# STM32L4x6 register map
File version: 1.5
CPU: CM4 r1p0, little endian, no MPU, FPU, 3 interrupt priority bits
Registers are 32-bit, read-write, reset 0x0 unless marked. A register's access mark holds for its fields unless they carry their own. Offsets are from the block's base; [hi:lo] are bit positions; {n}, {i} and the like mark numbered series; 'fields as' and 'values as' point back to an identical list.

## OTG_FS_HOST — USB on the go full speed
Base 0x50000400
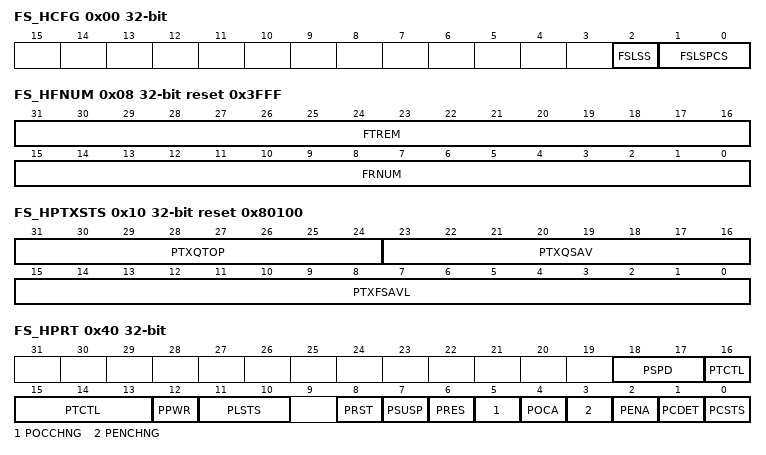
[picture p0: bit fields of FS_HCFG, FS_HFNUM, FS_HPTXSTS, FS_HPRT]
0x00 FS_HCFG access per field — OTG_FS host configuration register (OTG_FS_HCFG)
  [2] FSLSS ro — FS- and LS-only support
  [1:0] FSLSPCS rw — FS/LS PHY clock select
0x04 HFIR reset 0xEA60 — OTG_FS Host frame interval register
  [15:0] FRIVL — Frame interval
0x08 FS_HFNUM ro reset 0x3FFF — OTG_FS host frame number/frame time remaining register (OTG_FS_HFNUM)
  [31:16] FTREM — Frame time remaining
  [15:0] FRNUM — Frame number
0x10 FS_HPTXSTS access per field reset 0x80100 — OTG_FS_Host periodic transmit FIFO/queue status register (OTG_FS_HPTXSTS)
  [31:24] PTXQTOP ro — Top of the periodic transmit request queue
  [23:16] PTXQSAV ro — Periodic transmit request queue space available
  [15:0] PTXFSAVL rw — Periodic transmit data FIFO space available
0x14 HAINT ro — OTG_FS Host all channels interrupt register
  [15:0] HAINT — Channel interrupts
0x18 HAINTMSK — OTG_FS host all channels interrupt mask register
  [15:0] HAINTM — Channel interrupt mask
0x40 FS_HPRT access per field — OTG_FS host port control and status register (OTG_FS_HPRT)
  [18:17] PSPD ro — Port speed
  [16:13] PTCTL rw — Port test control
  [12] PPWR rw — Port power
  [11:10] PLSTS ro — Port line status
  [8] PRST rw — Port reset
  [7] PSUSP rw — Port suspend
  [6] PRES rw — Port resume
  [5] POCCHNG rw — Port overcurrent change
  [4] POCA ro — Port overcurrent active
  [3] PENCHNG rw — Port enable/disable change
  [2] PENA rw — Port enable
  [1] PCDET rw — Port connect detected
  [0] PCSTS ro — Port connect status
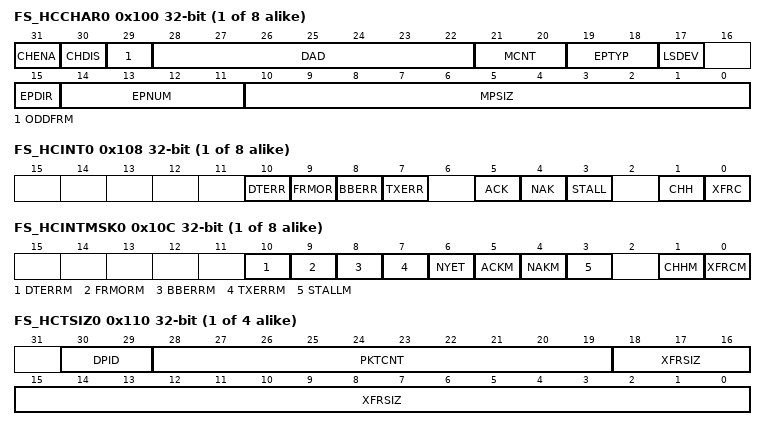
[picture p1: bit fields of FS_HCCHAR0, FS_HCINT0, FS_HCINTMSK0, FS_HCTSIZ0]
{0x100+0x20*i} FS_HCCHAR{i} (i=0..7) — OTG_FS host channel-{i} characteristics register (OTG_FS_HCCHAR{i})
  [31] CHENA — Channel enable
  [30] CHDIS — Channel disable
  [29] ODDFRM — Odd frame
  [28:22] DAD — Device address
  [21:20] MCNT — Multicount
  [19:18] EPTYP — Endpoint type
  [17] LSDEV — Low-speed device
  [15] EPDIR — Endpoint direction
  [14:11] EPNUM — Endpoint number
  [10:0] MPSIZ — Maximum packet size
{0x108+0x20*i} FS_HCINT{i} (i=0..7) — OTG_FS host channel-{i} interrupt register (OTG_FS_HCINT{i})
  [10] DTERR — Data toggle error
  [9] FRMOR — Frame overrun
  [8] BBERR — Babble error
  [7] TXERR — Transaction error
  [5] ACK — ACK response received/transmitted interrupt
  [4] NAK — NAK response received interrupt
  [3] STALL — STALL response received interrupt
  [1] CHH — Channel halted
  [0] XFRC — Transfer completed
{0x10C+0x20*i} FS_HCINTMSK{i} (i=0..7) — OTG_FS host channel-{i} mask register (OTG_FS_HCINTMSK{i})
  [10] DTERRM — Data toggle error mask
  [9] FRMORM — Frame overrun mask
  [8] BBERRM — Babble error mask
  [7] TXERRM — Transaction error mask
  [6] NYET — response received interrupt mask
  [5] ACKM — ACK response received/transmitted interrupt mask
  [4] NAKM — NAK response received interrupt mask
  [3] STALLM — STALL response received interrupt mask
  [1] CHHM — Channel halted mask
  [0] XFRCM — Transfer completed mask
{0x110+0x20*i} FS_HCTSIZ{i} (i=0..3) — OTG_FS host channel-{i} transfer size register
  [30:29] DPID — Data PID
  [28:19] PKTCNT — Packet count
  [18:0] XFRSIZ — Transfer size
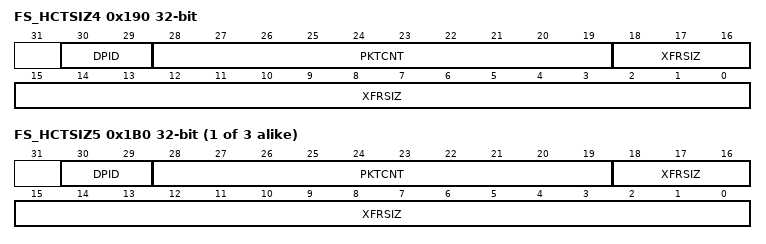
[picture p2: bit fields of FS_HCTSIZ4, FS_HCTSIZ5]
0x190 FS_HCTSIZ4 — OTG_FS host channel-x transfer size register
  fields as FS_HCTSIZ0
{0x110+0x20*i} FS_HCTSIZ{i} (i=5..7) — OTG_FS host channel-{i} transfer size register
  fields as FS_HCTSIZ0

## OTG_FS_PWRCLK — USB on the go full speed
Base 0x50000E00
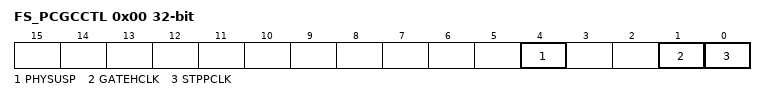
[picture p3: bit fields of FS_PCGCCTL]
0x00 FS_PCGCCTL — OTG_FS power and clock gating control register (OTG_FS_PCGCCTL)
  [4] PHYSUSP — PHY Suspended
  [1] GATEHCLK
  [0] STPPCLK — Stop PHY clock

## SWPMI1 — Single Wire Protocol Master Interface
Base 0x40008800
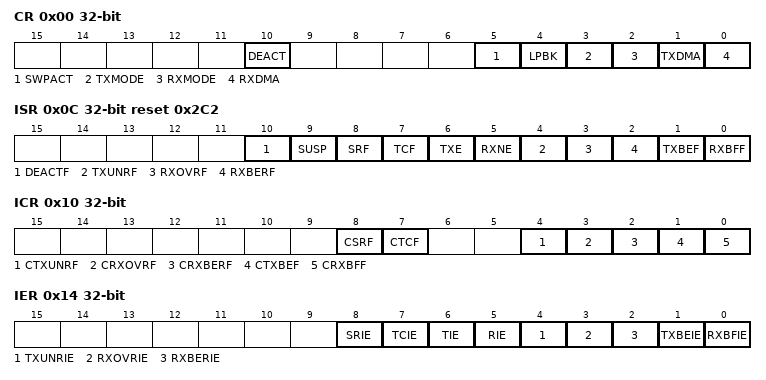
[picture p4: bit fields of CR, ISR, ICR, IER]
0x00 CR — SWPMI Configuration/Control register
  [10] DEACT — Single wire protocol master interface deactivate
  [5] SWPACT — Single wire protocol master interface activate
  [4] LPBK — Loopback mode enable
  [3] TXMODE — Transmission buffering mode
  [2] RXMODE — Reception buffering mode
  [1] TXDMA — Transmission DMA enable
  [0] RXDMA — Reception DMA enable
0x04 BRR reset 0x1 — SWPMI Bitrate register
  [5:0] BR — Bitrate prescaler
0x0C ISR ro reset 0x2C2 — SWPMI Interrupt and Status register
  [10] DEACTF — DEACTIVATED flag
  [9] SUSP — SUSPEND flag
  [8] SRF — Slave resume flag
  [7] TCF — Transfer complete flag
  [6] TXE — Transmit data register empty
  [5] RXNE — Receive data register not empty
  [4] TXUNRF — Transmit underrun error flag
  [3] RXOVRF — Receive overrun error flag
  [2] RXBERF — Receive CRC error flag
  [1] TXBEF — Transmit buffer empty flag
  [0] RXBFF — Receive buffer full flag
0x10 ICR wo — SWPMI Interrupt Flag Clear register
  [8] CSRF — Clear slave resume flag
  [7] CTCF — Clear transfer complete flag
  [4] CTXUNRF — Clear transmit underrun error flag
  [3] CRXOVRF — Clear receive overrun error flag
  [2] CRXBERF — Clear receive CRC error flag
  [1] CTXBEF — Clear transmit buffer empty flag
  [0] CRXBFF — Clear receive buffer full flag
0x14 IER — SWPMI Interrupt Enable register
  [8] SRIE — Slave resume interrupt enable
  [7] TCIE — Transmit complete interrupt enable
  [6] TIE — Transmit interrupt enable
  [5] RIE — Receive interrupt enable
  [4] TXUNRIE — Transmit underrun error interrupt enable
  [3] RXOVRIE — Receive overrun error interrupt enable
  [2] RXBERIE — Receive CRC error interrupt enable
  [1] TXBEIE — Transmit buffer empty interrupt enable
  [0] RXBFIE — Receive buffer full interrupt enable
0x18 RFL ro — SWPMI Receive Frame Length register
  [4:0] RFL — Receive frame length
0x1C TDR wo — SWPMI Transmit data register
  [31:0] TD — Transmit data
0x20 RDR ro — SWPMI Receive data register
  [31:0] RD — received data
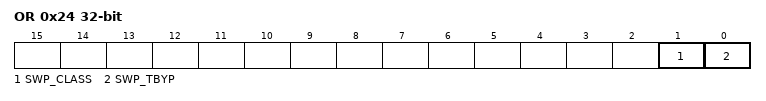
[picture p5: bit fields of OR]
0x24 OR — SWPMI Option register
  [1] SWP_CLASS — SWP class selection
  [0] SWP_TBYP — SWP transceiver bypass
